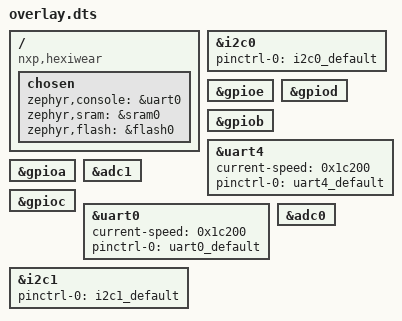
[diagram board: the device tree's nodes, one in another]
/ {
	compatible = "nxp,hexiwear", "nxp,k64f", "nxp,k6x";
	chosen {
		zephyr,console = &uart0;
		zephyr,sram = &sram0;
		zephyr,flash = &flash0;
	};
};
&i2c0{
	status = "okay";
	pinctrl-0 = < &i2c0_default >;
	pinctrl-names = "default";
};
&gpioe{
	status = "okay";
};
&gpiod{
	status = "okay";
};
&gpiob{
	status = "okay";
};
&uart4{
	status = "okay";
	current-speed = < 0x1c200 >;
	pinctrl-0 = < &uart4_default >;
	pinctrl-names = "default";
};
&gpioa{
	status = "okay";
};
&adc1{
	status = "okay";
};
&gpioc{
	status = "okay";
};
&uart0{
	status = "okay";
	current-speed = < 0x1c200 >;
	pinctrl-0 = < &uart0_default >;
	pinctrl-names = "default";
};
&i2c1{
	status = "okay";
	pinctrl-0 = < &i2c1_default >;
	pinctrl-names = "default";
};
&adc0{
	status = "okay";
};
